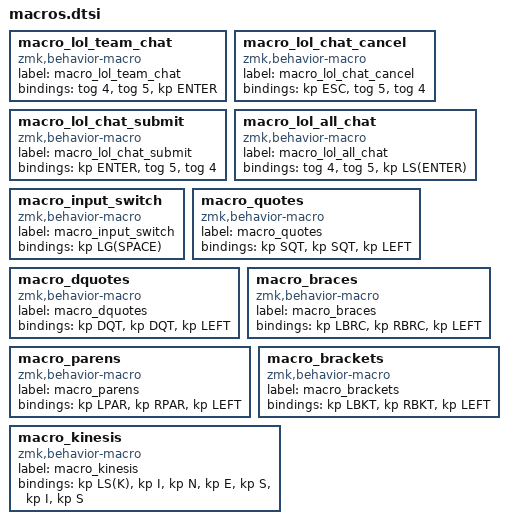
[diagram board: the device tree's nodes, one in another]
macro_lol_team_chat: macro_lol_team_chat{
compatible = "zmk,behavior-macro";
label = "macro_lol_team_chat";
#binding-cells = <0>;
bindings = <&tog 4>, <&tog 5>, <&kp ENTER>;
};
macro_lol_chat_cancel: macro_lol_chat_cancel{
compatible = "zmk,behavior-macro";
label = "macro_lol_chat_cancel";
#binding-cells = <0>;
bindings = <&kp ESC>, <&tog 5>, <&tog 4>;
};
macro_lol_chat_submit: macro_lol_chat_submit{
compatible = "zmk,behavior-macro";
label = "macro_lol_chat_submit";
#binding-cells = <0>;
bindings = <&kp ENTER>, <&tog 5>, <&tog 4>;
};
macro_lol_all_chat: macro_lol_all_chat{
compatible = "zmk,behavior-macro";
label = "macro_lol_all_chat";
#binding-cells = <0>;
bindings = <&tog 4>, <&tog 5>, <&kp LS(ENTER)>;
};
macro_input_switch: macro_input_switch{
compatible = "zmk,behavior-macro";
label = "macro_input_switch";
#binding-cells = <0>;
bindings = <&kp LG(SPACE)>;
};
macro_quotes: macro_quotes{
compatible = "zmk,behavior-macro";
label = "macro_quotes";
#binding-cells = <0>;
bindings = <&kp SQT>, <&kp SQT>, <&kp LEFT>;
};
macro_dquotes: macro_dquotes{
compatible = "zmk,behavior-macro";
label = "macro_dquotes";
#binding-cells = <0>;
bindings = <&kp DQT>, <&kp DQT>, <&kp LEFT>;
};
macro_braces: macro_braces{
compatible = "zmk,behavior-macro";
label = "macro_braces";
#binding-cells = <0>;
bindings = <&kp LBRC>, <&kp RBRC>, <&kp LEFT>;
};
macro_parens: macro_parens{
compatible = "zmk,behavior-macro";
label = "macro_parens";
#binding-cells = <0>;
bindings = <&kp LPAR>, <&kp RPAR>, <&kp LEFT>;
};
macro_brackets: macro_brackets{
compatible = "zmk,behavior-macro";
label = "macro_brackets";
#binding-cells = <0>;
bindings = <&kp LBKT>, <&kp RBKT>, <&kp LEFT>;
};
macro_kinesis: macro_kinesis{
compatible = "zmk,behavior-macro";
label = "macro_kinesis";
#binding-cells = <0>;
bindings = <&kp LS(K)>, <&kp I>, <&kp N>, <&kp E>, <&kp S>, <&kp I>, <&kp S>;
};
